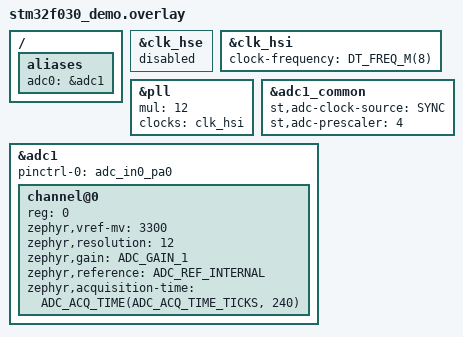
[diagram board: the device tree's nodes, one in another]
/*
 * Copyright (c) 2025 Hake Huang <hake.huang@gmail.com>.
 *
 * SPDX-License-Identifier: Apache-2.0
 */

/*
 * The second board on the bench has no HSE crystal populated, so the PLL is fed
 * from HSI/2 x 12 = 48 MHz like the power_shield branch does; without this the
 * clock init spins in LL_RCC_HSE_IsReady and the image never reaches printf().
 */
/* This board has no HSE crystal: disable it so the clock driver does not wait for it. */
&clk_hse {
	status = "disabled";
};

&clk_hsi {
clock-frequency = <DT_FREQ_M(8)>;
status = "okay";
};

&pll {
mul = <12>;
clocks = <&clk_hsi>;
};

/ {
aliases {
adc0 = &adc1;
};
};

/* Kernel clock and prescaler belong to the ADC common block. */
&adc1_common {
st,adc-clock-source = "SYNC";
st,adc-prescaler = <4>;
status = "okay";
};

&adc1 {
#io-channel-cells = <1>;
#address-cells = <1>;
#size-cells = <0>;
pinctrl-0 = <&adc_in0_pa0>;
pinctrl-names = "default";
status = "okay";

channel@0 {
reg = <0>;
zephyr,vref-mv = <3300>;
zephyr,resolution = <12>;
zephyr,gain = "ADC_GAIN_1";
zephyr,reference = "ADC_REF_INTERNAL";
zephyr,acquisition-time = <ADC_ACQ_TIME(ADC_ACQ_TIME_TICKS, 240)>;
};
};
